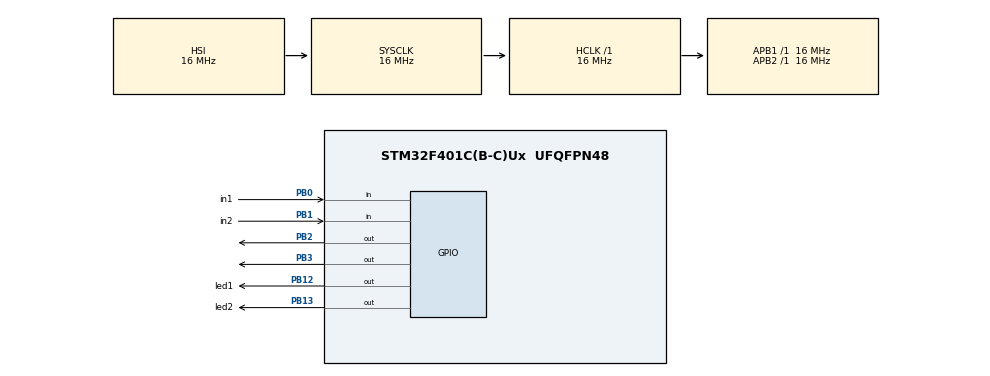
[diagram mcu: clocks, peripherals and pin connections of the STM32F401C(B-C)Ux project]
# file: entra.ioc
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Mcu.Family=STM32F4
Mcu.Name=STM32F401C(B-C)Ux
Mcu.Package=UFQFPN48
NVIC.PriorityGroup=NVIC_PRIORITYGROUP_4
PB0.GPIO_Label=in1
PB0.GPIO_PuPd=GPIO_PULLUP
PB0.Signal=GPIO_Input
PB1.GPIO_Label=in2
PB1.GPIO_PuPd=GPIO_PULLDOWN
PB1.Signal=GPIO_Input
PB12.GPIO_Label=led1
PB12.Signal=GPIO_Output
PB13.GPIO_Label=led2
PB13.Signal=GPIO_Output
PB2.Signal=GPIO_Output
PB3.Signal=GPIO_Output
PH0\ -\ OSC_IN.Mode=HSE-External-Oscillator
PH0\ -\ OSC_IN.Signal=RCC_OSC_IN
PH1\ -\ OSC_OUT.Mode=HSE-External-Oscillator
PH1\ -\ OSC_OUT.Signal=RCC_OSC_OUT
ProjectManager.HeapSize=0x200
ProjectManager.StackSize=0x400
ProjectManager.TargetToolchain=STM32CubeIDE
RCC.48MHZClocksFreq_Value=32000000
RCC.AHBFreq_Value=16000000
RCC.APB1Freq_Value=16000000
RCC.APB1TimFreq_Value=16000000
RCC.APB2Freq_Value=16000000
RCC.APB2TimFreq_Value=16000000
RCC.CortexFreq_Value=16000000
RCC.HCLKFreq_Value=16000000
RCC.HSE_VALUE=25000000
RCC.HSI_VALUE=16000000
RCC.LSE_VALUE=32768
RCC.PLLM=8
RCC.PLLN=64
RCC.SYSCLKFreq_VALUE=16000000
RCC.VCOOutputFreq_Value=128000000
board=custom

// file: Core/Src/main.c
/* USER CODE BEGIN Header */
/**
  ******************************************************************************
  * @file           : main.c
  * @brief          : Main program body
  ******************************************************************************
  * @attention
  *
  * Copyright (c) 2023 STMicroelectronics.
  * All rights reserved.
  *
  * This software is licensed under terms that can be found in the LICENSE file
  * in the root directory of this software component.
  * If no LICENSE file comes with this software, it is provided AS-IS.
  *
  ******************************************************************************
  */
/* USER CODE END Header */
#include "main.h"

/* USER CODE BEGIN Includes */
#include "stdio.h"
#include "stdlib.h"
#include "string.h"

/* USER CODE END Includes */

/* USER CODE BEGIN PD */
#define sw1 HAL_GPIO_ReadPin(in1_GPIO_Port, in1_Pin)
#define sw2 HAL_GPIO_ReadPin(in2_GPIO_Port, in2_Pin)
#define puerto  (in1_GPIO_Port->IDR& 0b1111)
/* USER CODE END PD */

void SystemClock_Config(void);
static void MX_GPIO_Init(void);

int main(void)
{

  /* MCU Configuration--------------------------------------------------------*/

  /* Reset of all peripherals, Initializes the Flash interface and the Systick. */
  HAL_Init();

  /* Configure the system clock */
  SystemClock_Config();

  /* Initialize all configured peripherals */
  MX_GPIO_Init();

  /* Infinite loop */
  /* USER CODE BEGIN WHILE */
  while (1)
  {

if (puerto >=5)  HAL_GPIO_TogglePin(led1_GPIO_Port, led1_Pin);
else HAL_GPIO_TogglePin(led2_GPIO_Port, led2_Pin);
HAL_Delay(200);

	/* if (sw1==0)
		 {
		 HAL_GPIO_TogglePin(led1_GPIO_Port, led1_Pin);
		  HAL_Delay(100);
		 }

	 if (sw2==1)
		 {
		 HAL_GPIO_TogglePin(led2_GPIO_Port, led2_Pin);
		  HAL_Delay(100);
		 }

		 */

    /* USER CODE END WHILE */

  }
}

void SystemClock_Config(void)
{
  RCC_OscInitTypeDef RCC_OscInitStruct = {0};
  RCC_ClkInitTypeDef RCC_ClkInitStruct = {0};

  /** Configure the main internal regulator output voltage
  */
  __HAL_RCC_PWR_CLK_ENABLE();
  __HAL_PWR_VOLTAGESCALING_CONFIG(PWR_REGULATOR_VOLTAGE_SCALE2);

  /** Initializes the RCC Oscillators according to the specified parameters
  * in the RCC_OscInitTypeDef structure.
  */
  RCC_OscInitStruct.OscillatorType = RCC_OSCILLATORTYPE_HSI;
  RCC_OscInitStruct.HSIState = RCC_HSI_ON;
  RCC_OscInitStruct.HSICalibrationValue = RCC_HSICALIBRATION_DEFAULT;
  RCC_OscInitStruct.PLL.PLLState = RCC_PLL_NONE;
  if (HAL_RCC_OscConfig(&RCC_OscInitStruct) != HAL_OK)
  {
    Error_Handler();
  }

  /** Initializes the CPU, AHB and APB buses clocks
  */
  RCC_ClkInitStruct.ClockType = RCC_CLOCKTYPE_HCLK|RCC_CLOCKTYPE_SYSCLK
                              |RCC_CLOCKTYPE_PCLK1|RCC_CLOCKTYPE_PCLK2;
  RCC_ClkInitStruct.SYSCLKSource = RCC_SYSCLKSOURCE_HSI;
  RCC_ClkInitStruct.AHBCLKDivider = RCC_SYSCLK_DIV1;
  RCC_ClkInitStruct.APB1CLKDivider = RCC_HCLK_DIV1;
  RCC_ClkInitStruct.APB2CLKDivider = RCC_HCLK_DIV1;

  if (HAL_RCC_ClockConfig(&RCC_ClkInitStruct, FLASH_LATENCY_0) != HAL_OK)
  {
    Error_Handler();
  }
}

static void MX_GPIO_Init(void)
{
  GPIO_InitTypeDef GPIO_InitStruct = {0};

  /* GPIO Ports Clock Enable */
  __HAL_RCC_GPIOH_CLK_ENABLE();
  __HAL_RCC_GPIOB_CLK_ENABLE();

  /*Configure GPIO pin Output Level */
  HAL_GPIO_WritePin(GPIOB, GPIO_PIN_2|led1_Pin|led2_Pin|GPIO_PIN_3, GPIO_PIN_RESET);

  /*Configure GPIO pin : in1_Pin */
  GPIO_InitStruct.Pin = in1_Pin;
  GPIO_InitStruct.Mode = GPIO_MODE_INPUT;
  GPIO_InitStruct.Pull = GPIO_PULLUP;
  HAL_GPIO_Init(in1_GPIO_Port, &GPIO_InitStruct);

  /*Configure GPIO pin : in2_Pin */
  GPIO_InitStruct.Pin = in2_Pin;
  GPIO_InitStruct.Mode = GPIO_MODE_INPUT;
  GPIO_InitStruct.Pull = GPIO_PULLDOWN;
  HAL_GPIO_Init(in2_GPIO_Port, &GPIO_InitStruct);

  /*Configure GPIO pins : PB2 led1_Pin led2_Pin PB3 */
  GPIO_InitStruct.Pin = GPIO_PIN_2|led1_Pin|led2_Pin|GPIO_PIN_3;
  GPIO_InitStruct.Mode = GPIO_MODE_OUTPUT_PP;
  GPIO_InitStruct.Pull = GPIO_NOPULL;
  GPIO_InitStruct.Speed = GPIO_SPEED_FREQ_LOW;
  HAL_GPIO_Init(GPIOB, &GPIO_InitStruct);

}

void Error_Handler(void)
{
  __disable_irq();
  while (1)
  {
  }
}
